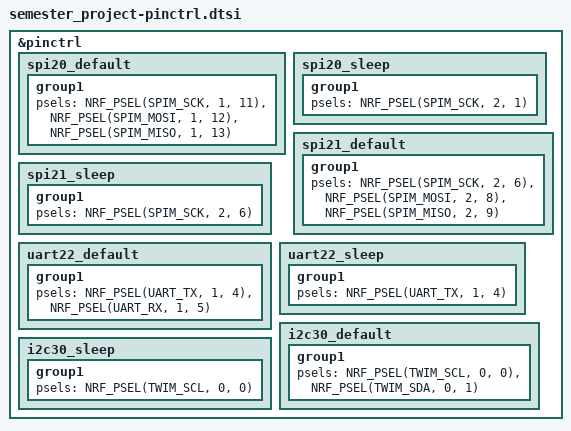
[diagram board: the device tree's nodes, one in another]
&pinctrl {
	spi20_default: spi20_default {
		group1 {
			psels = <NRF_PSEL(SPIM_SCK, 1, 11)>,
			        <NRF_PSEL(SPIM_MOSI, 1, 12)>,
			        <NRF_PSEL(SPIM_MISO, 1, 13)>;
		};
	};

	spi20_sleep: spi20_sleep {
		group1 {
			psels = <NRF_PSEL(SPIM_SCK, 2, 1)>;
		};
	};

	spi21_default: spi21_default {
		group1 {
			psels = <NRF_PSEL(SPIM_SCK, 2, 6)>,
			        <NRF_PSEL(SPIM_MOSI, 2, 8)>,
			        <NRF_PSEL(SPIM_MISO, 2, 9)>;
		};
	};

	spi21_sleep: spi21_sleep {
		group1 {
			psels = <NRF_PSEL(SPIM_SCK, 2, 6)>;
		};
	};

	uart22_default: uart22_default {
		group1 {
			psels = <NRF_PSEL(UART_TX, 1, 4)>, <NRF_PSEL(UART_RX, 1, 5)>;
		};
	};

	uart22_sleep: uart22_sleep {
		group1 {
			psels = <NRF_PSEL(UART_TX, 1, 4)>;
		};
	};

	i2c30_default: i2c30_default {
		group1 {
			psels = <NRF_PSEL(TWIM_SCL, 0, 0)>, <NRF_PSEL(TWIM_SDA, 0, 1)>;
		};
	};

	i2c30_sleep: i2c30_sleep {
		group1 {
			psels = <NRF_PSEL(TWIM_SCL, 0, 0)>;
		};
	};
};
